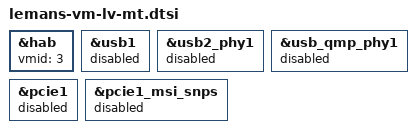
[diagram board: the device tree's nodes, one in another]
&hab {
	vmid = <3>;
};

&usb1 {
	status = "disabled";
};

&usb2_phy1 {
	status = "disabled";
};

&usb_qmp_phy1 {
	status = "disabled";
};

&pcie1 {
	status = "disabled";
};

&pcie1_msi_snps {
	status = "disabled";
};
